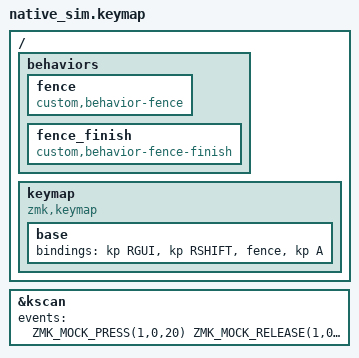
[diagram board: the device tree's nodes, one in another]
#include <dt-bindings/zmk/keys.h>
#include <behaviors.dtsi>
#include <dt-bindings/zmk/kscan_mock.h>
/ {
    behaviors {
        fence: fence { compatible = "custom,behavior-fence"; #binding-cells = <0>; };
        fence_finish: fence_finish { compatible = "custom,behavior-fence-finish"; #binding-cells = <0>; };
    };
    keymap {
        compatible = "zmk,keymap";
        base { bindings = <&kp RGUI &kp RSHIFT &fence &kp A>; };
    };
};
&kscan {
    events = <ZMK_MOCK_PRESS(1,0,20) ZMK_MOCK_RELEASE(1,0,20)
              ZMK_MOCK_PRESS(0,1,20) ZMK_MOCK_PRESS(1,0,20) ZMK_MOCK_RELEASE(1,0,20) ZMK_MOCK_RELEASE(0,1,20)
              ZMK_MOCK_PRESS(0,0,20) ZMK_MOCK_PRESS(1,0,20) ZMK_MOCK_RELEASE(1,0,20) ZMK_MOCK_RELEASE(0,0,20)
              ZMK_MOCK_PRESS(1,1,20) ZMK_MOCK_RELEASE(1,1,10)>;
};
